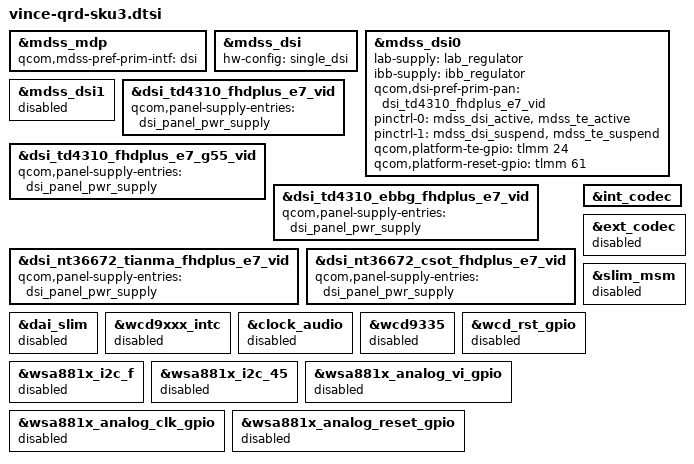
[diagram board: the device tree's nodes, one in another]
/*
 * Copyright (c) 2015-2016, The Linux Foundation. All rights reserved.
 *
 * This program is free software; you can redistribute it and/or modify
 * it under the terms of the GNU General Public License version 2 and
 * only version 2 as published by the Free Software Foundation.
 *
 * This program is distributed in the hope that it will be useful,
 * but WITHOUT ANY WARRANTY; without even the implied warranty of
 * MERCHANTABILITY or FITNESS FOR A PARTICULAR PURPOSE.  See the
 * GNU General Public License for more details.
 */

&mdss_mdp {
	qcom,mdss-pref-prim-intf = "dsi";
};

&mdss_dsi {
	hw-config = "single_dsi";
};

&mdss_dsi0 {
	lab-supply = <&lab_regulator>;
	ibb-supply = <&ibb_regulator>;
	/delete-property/ vdd-supply;
	qcom,dsi-pref-prim-pan = <&dsi_td4310_fhdplus_e7_vid>;
	pinctrl-names = "mdss_default", "mdss_sleep";
	pinctrl-0 = <&mdss_dsi_active &mdss_te_active>;
	pinctrl-1 = <&mdss_dsi_suspend &mdss_te_suspend>;
	qcom,platform-te-gpio = <&tlmm 24 0>;
	qcom,platform-reset-gpio = <&tlmm 61 0>;
};

&mdss_dsi1 {
	status = "disabled";
};

/*add begin for E7 display*/
&dsi_td4310_fhdplus_e7_vid {
	qcom,panel-supply-entries = <&dsi_panel_pwr_supply>;
};

&dsi_td4310_fhdplus_e7_g55_vid {
	qcom,panel-supply-entries = <&dsi_panel_pwr_supply>;
};


&dsi_td4310_ebbg_fhdplus_e7_vid {
	qcom,panel-supply-entries = <&dsi_panel_pwr_supply>;
};

&dsi_nt36672_tianma_fhdplus_e7_vid {
	qcom,panel-supply-entries = <&dsi_panel_pwr_supply>;
};

&dsi_nt36672_csot_fhdplus_e7_vid {
	qcom,panel-supply-entries = <&dsi_panel_pwr_supply>;
};
/*add end for E7 display*/

&int_codec {
	status = "ok";
};

&ext_codec {
	status = "disabled";
};

&slim_msm {
	status = "disabled";
};

&dai_slim {
	status = "disabled";
};

&wcd9xxx_intc {
	status = "disabled";
};

&clock_audio {
	status = "disabled";
};

&wcd9335 {
	status = "disabled";
};

&wcd_rst_gpio {
	status = "disabled";
};

&wsa881x_i2c_f {
        status = "disabled";
};
&wsa881x_i2c_45 {
        status = "disabled";
};
&wsa881x_analog_vi_gpio {
        status = "disabled";
};
&wsa881x_analog_clk_gpio {
        status = "disabled";
};
&wsa881x_analog_reset_gpio {
        status = "disabled";
};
